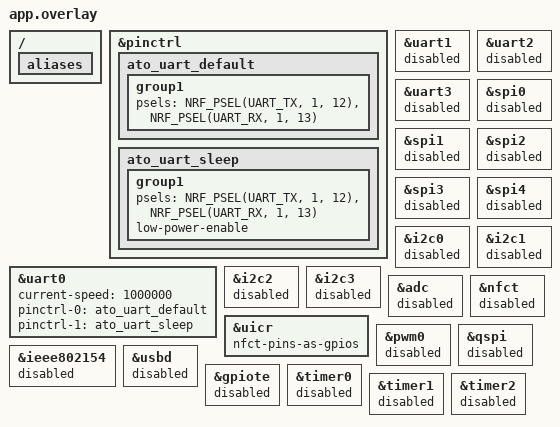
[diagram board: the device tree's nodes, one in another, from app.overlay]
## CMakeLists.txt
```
cmake_minimum_required(VERSION 3.20.0)
find_package(Zephyr REQUIRED HINTS $ENV{ZEPHYR_BASE})
project(ato_nrf5340)
target_sources(app PRIVATE src/main.c src/ato_backend.c ../core/ato_runtime.c)
target_include_directories(app PRIVATE ../core src)
target_compile_options(app PRIVATE -Wall -Wextra -Werror -Wno-unused-parameter)
```

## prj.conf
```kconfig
CONFIG_GPIO=n
CONFIG_SPI=n
CONFIG_NRFX_SPIM=y
CONFIG_SERIAL=y
CONFIG_UART_INTERRUPT_DRIVEN=y
CONFIG_UART_CONSOLE=n
CONFIG_CONSOLE=y
CONFIG_RTT_CONSOLE=y
CONFIG_USE_SEGGER_RTT=y
CONFIG_PRINTK=y
CONFIG_LOG=n
CONFIG_I2C=n
CONFIG_PWM=n
CONFIG_ADC=n
CONFIG_FLASH=n
CONFIG_NORDIC_QSPI_NOR=n
CONFIG_BT=n
CONFIG_PM=n
CONFIG_MAIN_STACK_SIZE=6144
CONFIG_SYSTEM_WORKQUEUE_STACK_SIZE=1024
CONFIG_HEAP_MEM_POOL_SIZE=0
CONFIG_ASSERT=y
CONFIG_BUILD_OUTPUT_BIN=y
CONFIG_BUILD_OUTPUT_HEX=y
CONFIG_FPU=y
```

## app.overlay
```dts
#include <zephyr/dt-bindings/pinctrl/nrf-pinctrl.h>
/ {
    /delete-node/ leds;
    /delete-node/ buttons;
    /delete-node/ pwmleds;
    /delete-node/ nrf-gpio-forwarder;
    aliases {
        /delete-property/ led0;
        /delete-property/ led1;
        /delete-property/ led2;
        /delete-property/ led3;
        /delete-property/ sw0;
        /delete-property/ sw1;
        /delete-property/ sw2;
        /delete-property/ sw3;
        /delete-property/ pwm-led0;
        /delete-property/ mcuboot-button0;
        /delete-property/ mcuboot-led0;
    };
};
&pinctrl {
    ato_uart_default: ato_uart_default {
        group1 { psels = <NRF_PSEL(UART_TX, 1, 12)>, <NRF_PSEL(UART_RX, 1, 13)>; };
    };
    ato_uart_sleep: ato_uart_sleep {
        group1 {
            psels = <NRF_PSEL(UART_TX, 1, 12)>, <NRF_PSEL(UART_RX, 1, 13)>;
            low-power-enable;
        };
    };
};
&uart0 {
    status = "okay";
    current-speed = <1000000>;
    pinctrl-0 = <&ato_uart_default>;
    pinctrl-1 = <&ato_uart_sleep>;
    pinctrl-names = "default", "sleep";
};
&uart1 { status = "disabled"; };
&uart2 { status = "disabled"; };
&uart3 { status = "disabled"; };
&spi0 { status = "disabled"; };
&spi1 { status = "disabled"; };
&spi2 { status = "disabled"; };
&spi3 { status = "disabled"; };
&spi4 { status = "disabled"; };
&i2c0 { status = "disabled"; };
&i2c1 { status = "disabled"; };
&i2c2 { status = "disabled"; };
&i2c3 { status = "disabled"; };
&adc { status = "disabled"; };
&nfct { status = "disabled"; };
&uicr { nfct-pins-as-gpios; };
&pwm0 { status = "disabled"; };
&qspi { status = "disabled"; };
&ieee802154 { status = "disabled"; };
&usbd { status = "disabled"; };
&gpiote { status = "disabled"; };
&timer0 { status = "disabled"; };
&timer1 { status = "disabled"; };
&timer2 { status = "disabled"; };
```

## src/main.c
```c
#include <zephyr/kernel.h>
#include <zephyr/sys/printk.h>
#include "ato_backend.h"

static ato_runtime runtime;

int main(void)
{
    ato_runtime_init(&runtime, 0);
    if (!ato_backend_init(&runtime)) {
        ato_backend_stop();
        ato_runtime_trip(&runtime, ATO_FAULT_CONFIG, 0x100, ato_backend_now_us());
        printk("ATO: commissioning failed, all requests inhibited\n");
    } else {
        printk("ATO: linked commissioning profile; explicit session/command/rearm required\n");
    }
    for (;;) {
        ato_backend_service(&runtime);
        /* No sleep is a timing guarantee. The lower-rate profile detects missed
         * slots, uses actual aperture brackets, and never catches up stale work. */
        k_yield();
    }
    return 0;
}
```

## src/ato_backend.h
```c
#ifndef ATO_BACKEND_H
#define ATO_BACKEND_H
#include "ato_runtime.h"
#include <stdbool.h>
#include <stdint.h>

typedef struct {
    uint64_t aperture_lo_us, aperture_hi_us;
    uint32_t epoch, capture_id;
    uint16_t code;
    uint8_t channel, valid;
} ato_raw_record;
typedef struct {
    uint64_t frame_lo_us;
    uint32_t aperture_offset_lo_us[16], aperture_offset_hi_us[16];
    int16_t samples[16];
    uint32_t epoch, sequence;
    uint16_t valid_mask, supply_code;
} ato_rhd_record;
typedef struct {
    uint64_t aperture_lo_us, aperture_hi_us;
    uint32_t epoch, event_id, reset_epoch;
    uint16_t code[2];
    uint8_t phase, source_mask, valid, reserved;
} ato_endpoint_record;
typedef struct {
    uint32_t raw_received, rhd_frames, endpoint_pairs, uart_rejects;
    uint32_t missed_raw_slots, missed_rhd_frames, telemetry_dropped;
    uint32_t latest_sideband, configuration_epoch, integrator_epoch;
    uint16_t envelope[16];
    uint8_t commissioned, observing;
} ato_backend_status;

bool ato_backend_init(ato_runtime *runtime);
uint64_t ato_backend_now_us(void);
void ato_backend_service(ato_runtime *runtime);
void ato_backend_stop(void);
const ato_backend_status *ato_backend_status_get(void);
#endif
```

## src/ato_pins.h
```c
#ifndef ATO_PINS_H
#define ATO_PINS_H
/* Logical carrier mapping, not a wiring instruction for an unmodified DK.
 * P0.00/.01 retain LFXO. P0.02/.03 require NFCT disabled in the overlay/UICR.
 * Four additional 165s serialize ACTUAL active Q and health, not candidate data. */
enum {
    PIN_PRELOAD=2, PIN_COMMIT=3, PIN_ROUTE_REARM=4, PIN_ROUTE_ACK=5,
    PIN_WANT0=6, PIN_WANT1=7,
    PIN_RAW_SCK=8, PIN_RAW_MOSI=9, PIN_RAW_MISO=10, PIN_RAW_CS=11,
    PIN_RAW_RESET=12,
    PIN_AFE_SCK=13, PIN_AFE_MOSI=14, PIN_AFE_MISO=15, PIN_AFE_CS=16,
    PIN_AFE_CONNECT=17, PIN_AFE_RECORD=18, PIN_AFE_FAULT=19,
    PIN_MON_SCK=20, PIN_MON_MISO=21, PIN_BOTH_CNV=22,
    PIN_MON_CS0=23, PIN_MON_CS1=24,
    PIN_INT_RUN0=25, PIN_INT_RUN1=26,
    PIN_MON_REARM0=27, PIN_MON_REARM1=28,
    PIN_CTRL_SCK=29, PIN_CTRL_MOSI=30, PIN_DAC_CS=31,
    PIN_REQ0=32, PIN_REQ1=33, PIN_PLUS0=34, PIN_MINUS0=35,
    PIN_PLUS1=36, PIN_MINUS1=37, PIN_DRV_REARM=38,
    PIN_SUP_REARM=39, PIN_FAULT_RESET=40, PIN_WDI=41,
    PIN_PHASE_REARM0=42, PIN_PHASE_REARM1=43,
    PIN_UART_TX=44, PIN_UART_RX=45, PIN_SIDEBAND_LOAD=46,
    PIN_SIDEBAND_DATA=47
};
#define SIDEBAND_SENTINEL_MASK UINT32_C(0xfc000000)
#define SIDEBAND_SENTINEL_VALUE UINT32_C(0xa4000000)
#define ATO_RAW_SLOT_US 100u
#define ATO_RHD_FRAME_US 1000u
#define ATO_RHD_WORDS 19u
#define ATO_RHD_SLOTS_US 8u
#define ATO_RHD_RECOVERY_US 10000u
#define ATO_RAW_RECORDS 256u
#define ATO_RHD_RECORDS 256u
#define ATO_ENDPOINT_RECORDS 64u
#endif
```
